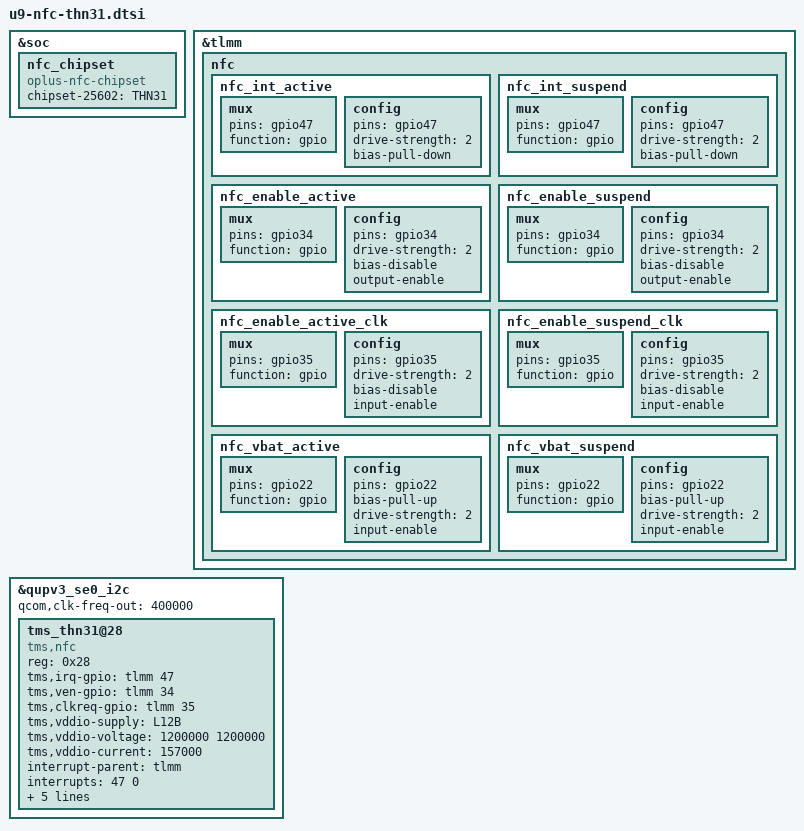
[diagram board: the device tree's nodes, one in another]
#include <dt-bindings/clock/qcom,rpmh.h>

&soc {
    //add for nfc_chipset
    nfc_chipset {
        compatible = "oplus-nfc-chipset";
        chipset-25602 = "THN31";
    };
};
&tlmm {
	nfc {
		nfc_int_active: nfc_int_active {
			/* active state */
			mux {
				/* NFC Read Interrupt */
				pins = "gpio47";
				function = "gpio";
			};

			config {
				pins = "gpio47";
				drive-strength = <2>; /* 2 MA */
				bias-pull-down;
			};
		};

		nfc_int_suspend: nfc_int_suspend {
			/* sleep state */
			mux {
				/* NFC Read Interrupt */
				pins = "gpio47";
				function = "gpio";
			};

			config {
				pins = "gpio47";
				drive-strength = <2>; /* 2 MA */
				bias-pull-down;
			};
		};

		nfc_enable_active: nfc_enable_active {
			mux {
				/* Enable, and Clock request gpios */
				pins = "gpio34";
				function = "gpio";
			};

			config {
				pins = "gpio34";
				drive-strength = <2>; /* 2 MA */
				bias-disable;
				output-enable;
			};
		};

		nfc_enable_suspend: nfc_enable_suspend {
			mux {
				pins = "gpio34";
				function = "gpio";
			};

			config {
				pins = "gpio34";
				drive-strength = <2>; /* 2 MA */
				bias-disable;
				output-enable;
			};
		};

		nfc_enable_active_clk: nfc_enable_active_clk {
			mux {
				/* Enable, and Clock request gpios */
				pins = "gpio35";
				function = "gpio";
			};

			config {
				pins = "gpio35";
				drive-strength = <2>; /* 2 MA */
				bias-disable;
				input-enable;
			};
		};

		nfc_enable_suspend_clk: nfc_enable_suspend_clk {
			mux {
				pins = "gpio35";
				function = "gpio";
			};

			config {
				pins = "gpio35";
				drive-strength = <2>; /* 2 MA */
				bias-disable;
				input-enable;
			};
		};

						nfc_vbat_active: nfc_vbat_active {
			mux {
				pins = "gpio22";
				function = "gpio";	// if configure it as other function, please check struct msm_pingroup[](in pinctrl-<soc>.c) for the other function name.
			};

			config {
				pins = "gpio22";
				bias-pull-up; //The bias configuraion is for input GPIO. it could be bias-pull-down/bias-pull-up/bias-disable(means no pull)
				drive-strength = <2>; // the strength is for output GPIO, the valuse could be 2/4/6/8/10/12/14/16 ma according to you hardware requirement.
				//output-high; //for output GPIO, it could be output-high or output-low.
				input-enable; // this is for input GPIO
			};
		};

		nfc_vbat_suspend: nfc_vbat_suspend {
			mux {
				pins = "gpio22";
				function = "gpio";	// if configure it as other function, please check struct msm_pingroup[](in pinctrl-<soc>.c) for the other function name.
			};

			config {
				pins = "gpio22";
				bias-pull-up; //The bias configuraion is for input GPIO. it could be bias-pull-down/bias-pull-up/bias-disable(means no pull)
				drive-strength = <2>; // the strength is for output GPIO, the valuse could be 2/4/6/8/10/12/14/16 ma according to you hardware requirement.
				//output-high; //for output GPIO, it could be output-high or output-low.
				input-enable; // this is for input GPIO
			};
		};
	}; //nfc
}; //tlmm
&qupv3_se0_i2c {
	status = "ok";
	qcom,clk-freq-out = <400000>;
	#address-cells = <1>;
	#size-cells = <0>;
	tms_thn31@28 {
		compatible = "tms,nfc";
		reg = <0x28>;
		tms,irq-gpio = <&tlmm 47 0x00>;
		tms,ven-gpio = <&tlmm 34 0x00>;
		tms,clkreq-gpio = <&tlmm 35 0x00>;
		tms,vddio-supply = <&L12B>;
		tms,vddio-voltage = <1200000 1200000>;
		tms,vddio-current = <157000>;
		interrupt-parent = <&tlmm>;
		interrupts = <47 0>;
		interrupt-names = "nfc_irq";
		pinctrl-names = "nfc_active", "nfc_suspend";
		pinctrl-0 = <&nfc_int_active &nfc_enable_active &nfc_enable_active_clk &nfc_vbat_active>;
		pinctrl-1 = <&nfc_int_suspend &nfc_enable_suspend &nfc_enable_suspend_clk &nfc_vbat_suspend>;
	};
};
